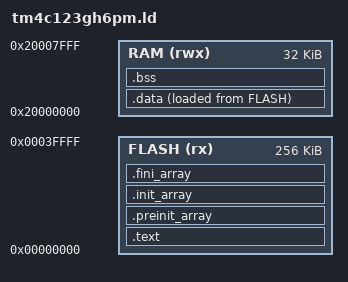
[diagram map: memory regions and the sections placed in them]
MEMORY
{
    FLASH (rx) : ORIGIN = 0x00000000, LENGTH = 256K
    RAM (rwx)  : ORIGIN = 0x20000000, LENGTH = 32K
}

SECTIONS
{
    .text :
    {
        _text = .;
        KEEP(*(.isr_vector))
        *(.text*)
        *(.rodata*)
        
        /* C++ Constructors / Destructors */
        KEEP(*(.init))
        KEEP(*(.fini))

        _etext = .;
    } > FLASH

    /* CRITICAL: Arrays of pointers to initialization functions */
    .preinit_array :
    {
        PROVIDE_HIDDEN (__preinit_array_start = .);
        KEEP (*(.preinit_array*))
        PROVIDE_HIDDEN (__preinit_array_end = .);
    } > FLASH

    .init_array :
    {
        PROVIDE_HIDDEN (__init_array_start = .);
        KEEP (*(SORT(.init_array.*)))
        KEEP (*(.init_array*))
        PROVIDE_HIDDEN (__init_array_end = .);
    } > FLASH

    .fini_array :
    {
        PROVIDE_HIDDEN (__fini_array_start = .);
        KEEP (*(SORT(.fini_array.*)))
        KEEP (*(.fini_array*))
        PROVIDE_HIDDEN (__fini_array_end = .);
    } > FLASH

    .data :
    {
        _data = .;
        *(vtable)
        *(.data*)
        _edata = .;
    } > RAM AT > FLASH

    .bss :
    {
        _bss = .;
        *(.bss*)
        *(COMMON)
        _ebss = .;
    } > RAM

    PROVIDE(end = .);
}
